# AC7842x register map
Vendor: AutoChips; Series: AC78; File version: 1.0
CPU: CM4 r0p1, little endian, MPU, FPU, VTOR, 4 interrupt priority bits
Registers are 32-bit, read-write, reset 0x0 unless marked. A register's access mark holds for its fields unless they carry their own. Offsets are from the block's base; [hi:lo] are bit positions.

## DMA0_TOP_RST — DMA0 All Channnels Share The Registers
Base 0x40012000
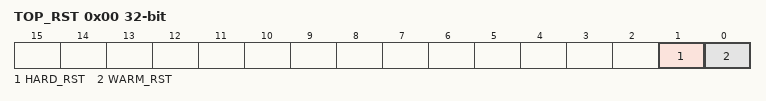
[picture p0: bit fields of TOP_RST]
0x00 TOP_RST reset not defined
  [1] HARD_RST — hard reset
    0=Disable; 1=Enable
  [0] WARM_RST — warm reset
    0=Disable; 1=Enable

## WDG — Watchdog
Base 0x4000B000
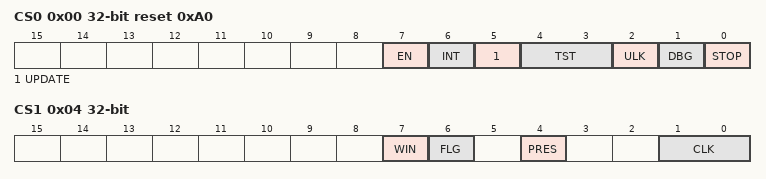
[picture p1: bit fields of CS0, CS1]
0x00 CS0 reset 0xA0 (reset mask 0xFB) — Watchdog Control and Status Register 0
  [7] EN — Watchdog Enable
    0=Watchdog disabled; 1=Watchdog enabled
  [6] INT — Watchdog Interrupt Enable
    0=Watchdog interrupts are disabled. Watchdog resets are not delayed.; 1=Watchdog interrupts are enabled. Watchdog resets are delayed by 128 bus clocks.
  [5] UPDATE — Allow Updates Watchdog Config
    0=Updates not allowed. After the initial configuration, the watchdog cannot be later modified without forcing a reset.; 1=Updates allowed. Software can modify the watchdog configuration registers within 128 bus clocks after performing the unlock write sequence.
  [4:3] TST — Fast Test Mode Config
    0=Watchdog normal mode enabled; 2=Watchdog test mode enabled
  [2] ULK ro — Watchdog Unlock Status
    0=Watchdog is locked; 1=Watchdog is unlocked
  [1] DBG — Watchdog Debug Enable Bit
    0=Watchdog is disabled in chip debug mode; 1=Watchdog is enabled in chip debug mode
  [0] STOP — Watchdog Stop Enable Bit
    0=Watchdog is disabled in chip stop mode; 1=Watchdog is enabled in chip stop mode
0x04 CS1 — Watchdog Control and Status Register 1
  [7] WIN — Watchdog Window Enable
    0=Window mode disabled; 1=Window mode enabled
  [6] FLG — Watchdog Interrupt Flag
    0=No interrupt occurred; 1=An interrupt occurred
  [4] PRES — Watchdog Prescaler
    0=256 prescaler disabled; 1=256 prescaler enabled
  [1:0] CLK — Watchdog Clock Source
    0=LSI Clock; 1=Bus Clock; 2=VHSI_8M Clock; 3=HSE Clock
0x08 CNT — Watchdog Counter Value
  [31:0] CNT — Counter Value
0x0C TOVAL reset 0x5000 — Watchdog Timeout Value Register
  [15:0] TOVAL — Timeout Value
0x10 WIN — Watchdog Window Register
  [15:0] WIN — Window Value

## RTC — Real-time counter
Base 0x40009800
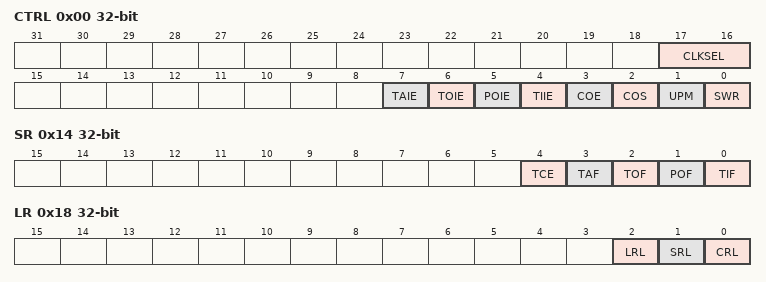
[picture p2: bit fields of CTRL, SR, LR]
0x00 CTRL (reset mask 0x10FF) — RTC Control Register
  [17:16] CLKSEL — RTC Clock Source Select
    0=HSE Clock; 1=VHSI Clock; 2=LSI32K Clock; 3=RTC in Clock
  [7] TAIE — RTC Time Alarm Interrupt Enable
    0=Time Alarm interrupt is disabled; 1=Time Alarm interrupt is enabled
  [6] TOIE — RTC Time Counter Overflow Interrupt Enable
    0=Time Counter Overflow interrupt is disabled; 1=Time Counter Overflow interrupt is enabled
  [5] POIE — RTC Prescaler Counter Overflow Interrupt Enable
    0=Prescaler Counter overflow interrupt is disabled; 1=Prescaler Counter overflow interrupt is enabled
  [4] TIIE — RTC Invalid Interrupt Enable
    0=Invalid interrupt is disabled; 1=Invalid interrupt is enabled
  [3] COE — RTC RTC_CLKOUT Enable
    0=RTC_CLKOUT function is disabled; 1=RTC_CLKOUT function is enabled
  [2] COS — RTC RTC_CLKOUT Selection
    0=Prescaler overflow flag output as RTC_CLKOUT; 1=RTC_CLK source output as RTC_CLKOUT
  [1] UPM — RTC Update Mode
    0=RTC_EN cannot be written when status register locked; 1=RTC_EN can be written when status register locked under limited conditions
  [0] SWR — RTC Software Reset
    0=No effect; 1=Resets all RTC register except for the SWR and CLKSEL bit
0x04 TAR — RTC Time Alarm Register
  [31:0] TAR — Time Alarm Register
0x08 TC — RTC Time Counter
0x0C PSR — RTC Prescaler Register
  [19:0] PSR — Prescale Value
0x10 PSC ro — RTC Prescaler Counter Register
  [19:0] PSC — Prescaler Counter Register
0x14 SR — RTC Status Register
  [4] TCE — RTC Enable
    0=RTC is disabled; 1=RTC is enabled
  [3] TAF ro — Time Alarm Flag
    0=Time alarm has not occurred; 1=Time alarm has occurred
  [2] TOF ro — Time Counter Overflow Flag
    0=Time counter overflow has not occurred; 1=Time counter overflow has occurred
  [1] POF — Prescaler Counter Overflow Flag
    0=Prescaler counter overflow has not occurred; 1=Prescaler counter overflow has occurred
  [0] TIF ro — Time Invalid Flag
    0=Time is valid; 1=Time is invalid
0x18 LR — RTC Lock Register
  [2] LRL — Lock Register Lock
    0=Lock register is unlocked; 1=Lock register is locked
  [1] SRL — Status Register Lock
    0=Status register is unlocked; 1=Status register is locked
  [0] CRL — Control Register Lock
    0=Control register is unlocked; 1=Control register is locked
